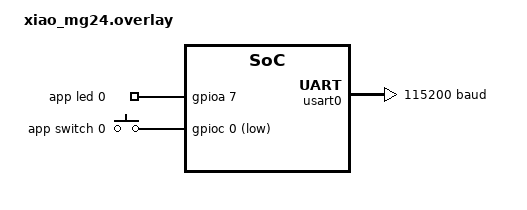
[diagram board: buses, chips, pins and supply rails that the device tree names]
/ {
    gpiocustom {
        compatible = "gpio-keys";
        appled0: appled_0 {
            gpios = <&gpioa 7 GPIO_ACTIVE_HIGH>;
            label = "app led 0";
        };

        appsw_0: appsw_0 {
            gpios = <&gpioc 0 (GPIO_PULL_UP | GPIO_ACTIVE_LOW)>;
            label = "app switch 0";
        };
    };

    aliases {
        appled0 = &appled0;
        appsw0 = &appsw_0;
        appuart0 = &usart0;
    };
};

&usart0 {
	current-speed = <115200>;
	pinctrl-0 = <&usart0_default>;
	pinctrl-names = "default";
	status = "okay";
};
